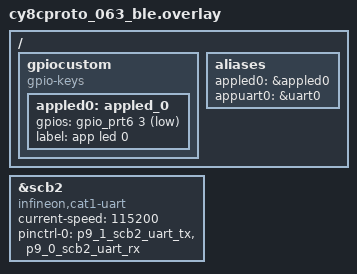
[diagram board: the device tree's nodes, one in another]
/ {
    gpiocustom {
        compatible = "gpio-keys";
        appled0: appled_0 {
            gpios = <&gpio_prt6 3 GPIO_ACTIVE_LOW>;
            label = "app led 0";
        };
    };

    aliases {
        appled0 = &appled0;
        appuart0 = &uart0;
    };
};

uart0: &scb2 {
	compatible = "infineon,cat1-uart";
	status = "okay";
	current-speed = <115200>;

	/* UART pins */
	pinctrl-0 = <&p9_1_scb2_uart_tx &p9_0_scb2_uart_rx>;
	pinctrl-names = "default";
};
